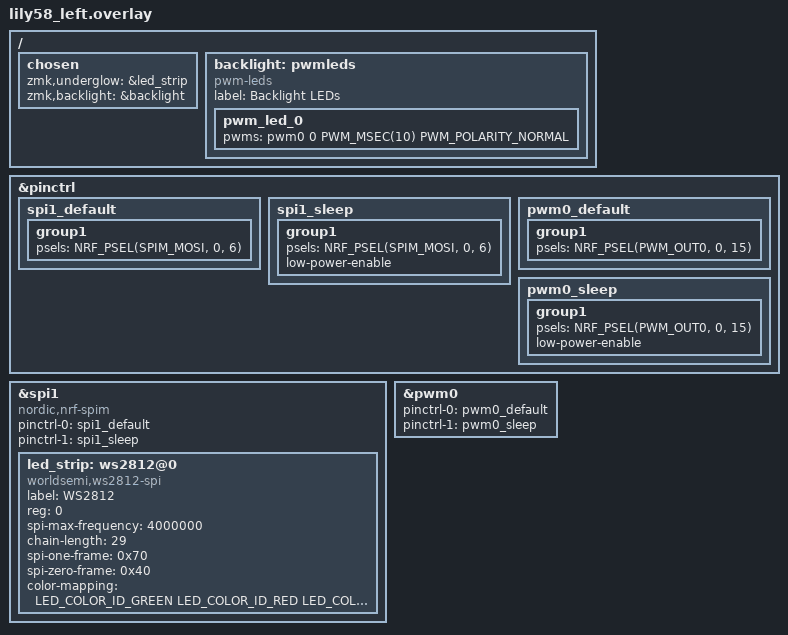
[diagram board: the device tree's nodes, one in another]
#include <dt-bindings/led/led.h>
#include <dt-bindings/pwm/pwm.h>

/* RGB Underglow Configuration */
&pinctrl {
    spi1_default: spi1_default {
        group1 {
            psels = <NRF_PSEL(SPIM_MOSI, 0, 6)>;
        };
    };

    spi1_sleep: spi1_sleep {
        group1 {
            psels = <NRF_PSEL(SPIM_MOSI, 0, 6)>;
            low-power-enable;
        };
    };

    /* PWM pin configuration for backlight */
    pwm0_default: pwm0_default {
        group1 {
            psels = <NRF_PSEL(PWM_OUT0, 0, 15)>; /* P0.15 for backlight */
        };
    };

    pwm0_sleep: pwm0_sleep {
        group1 {
            psels = <NRF_PSEL(PWM_OUT0, 0, 15)>;
            low-power-enable;
        };
    };
};

/* RGB Underglow SPI */
&spi1 {
    compatible = "nordic,nrf-spim";
    status = "okay";

    pinctrl-0 = <&spi1_default>;
    pinctrl-1 = <&spi1_sleep>;
    pinctrl-names = "default", "sleep";

    led_strip: ws2812@0 {
        compatible = "worldsemi,ws2812-spi";
        label = "WS2812";
        reg = <0>;
        spi-max-frequency = <4000000>;
        chain-length = <29>; /* 29 underglow LEDs per side */
        spi-one-frame = <0x70>;
        spi-zero-frame = <0x40>;
        color-mapping = <LED_COLOR_ID_GREEN LED_COLOR_ID_RED LED_COLOR_ID_BLUE>;
    };
};

/* PWM Backlight */
&pwm0 {
    status = "okay";
    pinctrl-0 = <&pwm0_default>;
    pinctrl-1 = <&pwm0_sleep>;
    pinctrl-names = "default", "sleep";
};

/ {
    chosen {
        zmk,underglow = &led_strip;
        zmk,backlight = &backlight;
    };

    backlight: pwmleds {
        compatible = "pwm-leds";
        label = "Backlight LEDs";
        pwm_led_0 {
            pwms = <&pwm0 0 PWM_MSEC(10) PWM_POLARITY_NORMAL>;
        };
    };
};
